VERSION ""

NS_ :

BS_:

BU_: INV BMS VCU BMS Third_Party_Device

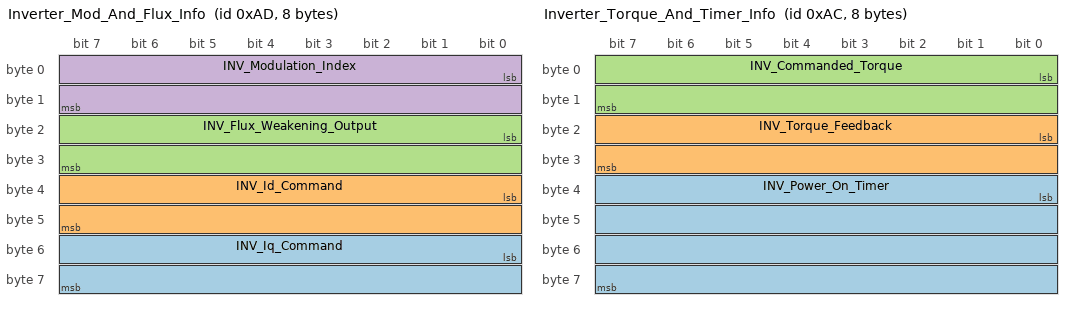
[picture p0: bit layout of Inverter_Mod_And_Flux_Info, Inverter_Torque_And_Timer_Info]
BO_ 173 Inverter_Mod_And_Flux_Info: 8 INV
 SG_ INV_Iq_Command : 48|16@1- (0.1,0) [-3276.8|3276.7] "current:A" Vector__XXX
 SG_ INV_Id_Command : 32|16@1- (0.1,0) [-3276.8|3276.7] "current:A" Vector__XXX
 SG_ INV_Flux_Weakening_Output : 16|16@1- (0.1,0) [-3276.8|3276.7] "current:A" Vector__XXX
 SG_ INV_Modulation_Index : 0|16@1- (0.0001,0) [-3.2768|3.2767] "" Vector__XXX

BO_ 172 Inverter_Torque_And_Timer_Info: 8 INV
 SG_ INV_Power_On_Timer : 32|32@1+ (0.003,0) [0|12884800] "time:second" Vector__XXX
 SG_ INV_Torque_Feedback : 16|16@1- (0.1,0) [-3276.8|3276.7] "torque:N.m" Vector__XXX
 SG_ INV_Commanded_Torque : 0|16@1- (0.1,0) [-3276.8|3276.7] "torque:N.m" Vector__XXX

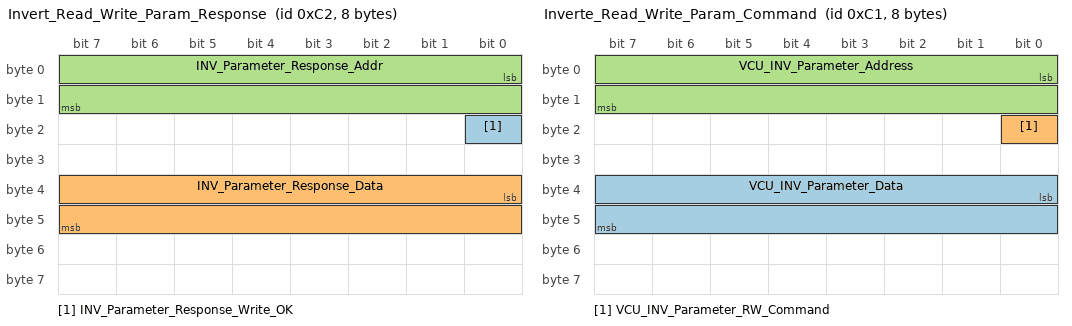
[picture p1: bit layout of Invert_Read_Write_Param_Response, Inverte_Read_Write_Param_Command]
BO_ 194 Invert_Read_Write_Param_Response: 8 INV
 SG_ INV_Parameter_Response_Write_OK : 16|1@1+ (1,0) [0|1] "" Vector__XXX
 SG_ INV_Parameter_Response_Data : 32|16@1- (1,0) [-32768|32767] "" Vector__XXX
 SG_ INV_Parameter_Response_Addr : 0|16@1+ (1,0) [0|65535] "" Vector__XXX

BO_ 193 Inverte_Read_Write_Param_Command: 8 VCU
 SG_ VCU_INV_Parameter_Data : 32|16@1- (1,0) [-32768|32767] "" Vector__XXX
 SG_ VCU_INV_Parameter_RW_Command : 16|1@1+ (1,0) [0|1] "" Vector__XXX
 SG_ VCU_INV_Parameter_Address : 0|16@1+ (1,0) [0|65535] "" Vector__XXX

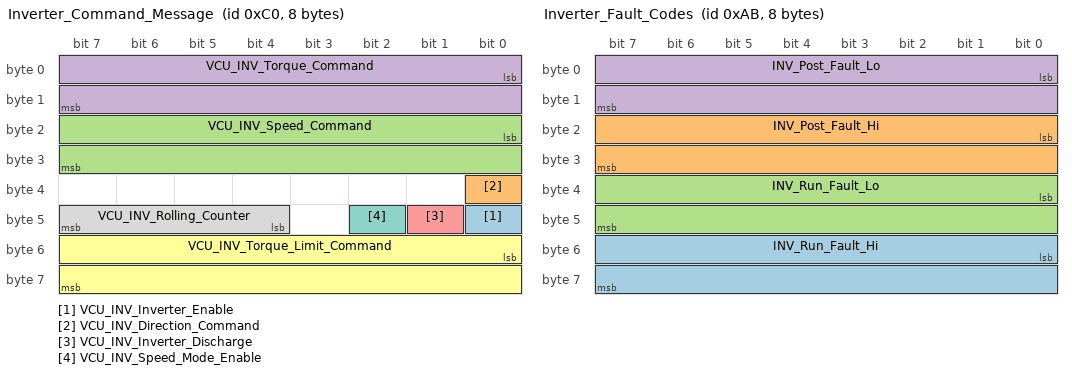
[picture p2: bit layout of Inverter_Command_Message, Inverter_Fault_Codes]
BO_ 192 Inverter_Command_Message: 8 VCU
 SG_ VCU_INV_Inverter_Enable : 40|1@1+ (1,0) [0|1] "" Vector__XXX
 SG_ VCU_INV_Direction_Command : 32|1@1+ (1,0) [0|1] "" Vector__XXX
 SG_ VCU_INV_Speed_Command : 16|16@1- (1,0) [-32768|32767] "angular_speed:rpm" Vector__XXX
 SG_ VCU_INV_Torque_Command : 0|16@1- (0.1,0) [-3276.8|3276.7] "torque:N.m" Vector__XXX
 SG_ VCU_INV_Inverter_Discharge : 41|1@1+ (1,0) [0|1] "" Vector__XXX
 SG_ VCU_INV_Torque_Limit_Command : 48|16@1- (0.1,0) [-3276.8|3276.7] "torque:N.m" Vector__XXX
 SG_ VCU_INV_Speed_Mode_Enable : 42|1@1+ (1,0) [0|1] "" Vector__XXX
 SG_ VCU_INV_Rolling_Counter : 44|4@1+ (1,0) [0|15] "" Vector__XXX

BO_ 171 Inverter_Fault_Codes: 8 INV
 SG_ INV_Run_Fault_Hi : 48|16@1+ (1,0) [0|65535] "" Vector__XXX
 SG_ INV_Post_Fault_Hi : 16|16@1+ (1,0) [0|65535] "" Vector__XXX
 SG_ INV_Run_Fault_Lo : 32|16@1+ (1,0) [0|65535] "" Vector__XXX
 SG_ INV_Post_Fault_Lo : 0|16@1+ (1,0) [0|65535] "" Vector__XXX

BO_ 170 Inverter_Internal_States: 8 INV
 SG_ INV_Direction_Command : 56|1@1+ (1,0) [0|1] "" Vector__XXX
 SG_ INV_Inverter_Enable_State : 48|1@1+ (1,0) [0|1] "" Vector__XXX
 SG_ INV_Relay_3_Status : 26|1@1+ (1,0) [0|1] "" Vector__XXX
 SG_ INV_Relay_4_Status : 27|1@1+ (1,0) [0|1] "" Vector__XXX
 SG_ INV_Relay_2_Status : 25|1@1+ (1,0) [0|1] "" Vector__XXX
 SG_ INV_Inverter_Run_Mode : 32|1@1+ (1,0) [0|1] "" Vector__XXX
 SG_ INV_Inverter_Command_Mode : 40|1@1+ (1,0) [0|1] "" Vector__XXX
 SG_ INV_Relay_1_Status : 24|1@1+ (1,0) [0|1] "" Vector__XXX
 SG_ INV_Inverter_State : 16|8@1+ (1,0) [0|255] "" Vector__XXX
 SG_ INV_VSM_State : 0|8@1+ (1,0) [0|15] "" Vector__XXX
 SG_ INV_Inverter_Enable_Lockout : 55|1@1+ (1,0) [0|1] "" Vector__XXX
 SG_ INV_Inverter_Discharge_State : 37|3@1+ (1,0) [0|7] "" Vector__XXX
 SG_ INV_Relay_5_Status : 28|1@1+ (1,0) [0|1] "" Vector__XXX
 SG_ INV_Relay_6_Status : 29|1@1+ (1,0) [0|1] "" Vector__XXX
 SG_ INV_BMS_Active : 57|1@1+ (1,0) [0|1] "" Vector__XXX
 SG_ INV_BMS_Limiting_Motor_Torque : 58|1@1+ (1,0) [0|1] "" Vector__XXX
 SG_ INV_PWM_Frequency : 8|8@1+ (1,0) [0|255] "" Vector__XXX
 SG_ INV_Limit_Max_Speed : 59|1@1+ (1,0) [0|1] "" Vector__XXX
 SG_ INV_Limit_Hot_Spot : 60|1@1+ (1,0) [0|1] "" Vector__XXX
 SG_ INV_Low_Speed_Limiting : 61|1@1+ (1,0) [0|1] "" Vector__XXX
 SG_ INV_Rolling_Counter : 44|4@1+ (1,0) [0|15] "" Vector__XXX
 SG_ INV_Limit_Coolant_Derating : 62|1@1+ (1,0) [0|1] "" Vector__XXX
 SG_ INV_Self_Sensing_Assist_Enable : 33|1@1+ (1,0) [0|1] "" Vector__XXX
 SG_ INV_Limit_Stall_Burst_Model : 63|1@1+ (1,0) [0|1] "" Vector__XXX
 SG_ INV_Burst_Model_Mode : 49|1@1+ (1,0) [0|1] "" Vector__XXX
 SG_ INV_Key_Switch_Start_Status : 54|1@1+ (1,0) [0|1] "" Vector__XXX
 SG_ INV_BMS_Limiting_Regen_Torque : 50|1@1+ (1,0) [0|0] "" Vector__XXX

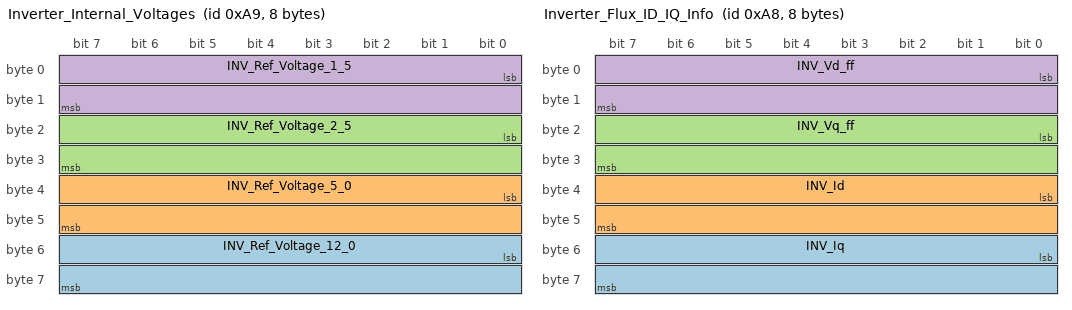
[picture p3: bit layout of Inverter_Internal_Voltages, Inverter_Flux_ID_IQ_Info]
BO_ 169 Inverter_Internal_Voltages: 8 INV
 SG_ INV_Ref_Voltage_12_0 : 48|16@1- (0.01,0) [-327.68|327.67] "voltage:V" Vector__XXX
 SG_ INV_Ref_Voltage_5_0 : 32|16@1- (0.01,0) [-327.68|327.67] "voltage:V" Vector__XXX
 SG_ INV_Ref_Voltage_2_5 : 16|16@1- (0.01,0) [-327.68|327.67] "voltage:V" Vector__XXX
 SG_ INV_Ref_Voltage_1_5 : 0|16@1- (0.01,0) [-327.68|327.67] "voltage:V" Vector__XXX

BO_ 168 Inverter_Flux_ID_IQ_Info: 8 INV
 SG_ INV_Iq : 48|16@1- (0.1,0) [-3276.8|3276.7] "current:A" Vector__XXX
 SG_ INV_Id : 32|16@1- (0.1,0) [-3276.8|3276.7] "current:A" Vector__XXX
 SG_ INV_Vq_ff : 16|16@1- (0.1,0) [-3276.7|3276.7] "voltage:V" Vector__XXX
 SG_ INV_Vd_ff : 0|16@1- (0.1,0) [-3276.7|3276.7] "voltage:V" Vector__XXX

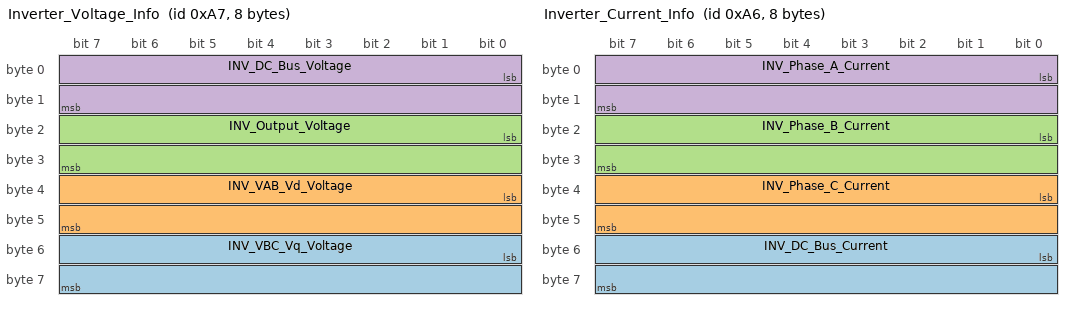
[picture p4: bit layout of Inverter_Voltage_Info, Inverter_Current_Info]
BO_ 167 Inverter_Voltage_Info: 8 INV
 SG_ INV_VBC_Vq_Voltage : 48|16@1- (0.1,0) [-3276.8|3276.7] "voltage:V" Vector__XXX
 SG_ INV_VAB_Vd_Voltage : 32|16@1- (0.1,0) [-3276.8|3276.7] "voltage:V" Vector__XXX
 SG_ INV_Output_Voltage : 16|16@1- (0.1,0) [-3276.8|3276.7] "voltage:V" Vector__XXX
 SG_ INV_DC_Bus_Voltage : 0|16@1- (0.1,0) [-3276.8|3276.7] "voltage:V" Vector__XXX

BO_ 166 Inverter_Current_Info: 8 INV
 SG_ INV_DC_Bus_Current : 48|16@1- (0.1,0) [-3276.8|3276.7] "current:A" Vector__XXX
 SG_ INV_Phase_C_Current : 32|16@1- (0.1,0) [-3276.8|3276.7] "current:A" Vector__XXX
 SG_ INV_Phase_B_Current : 16|16@1- (0.1,0) [-3276.8|3276.7] "current:A" Vector__XXX
 SG_ INV_Phase_A_Current : 0|16@1- (0.1,0) [-3276.8|3276.7] "current:A" Vector__XXX

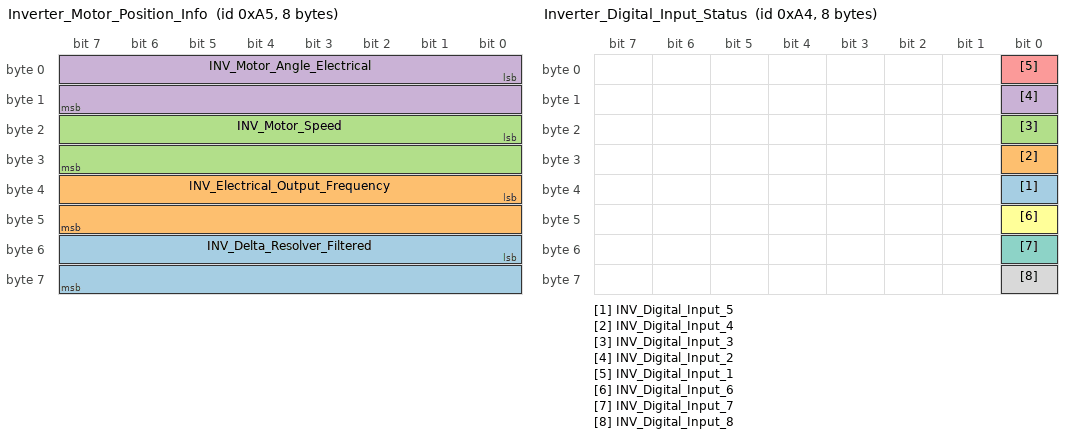
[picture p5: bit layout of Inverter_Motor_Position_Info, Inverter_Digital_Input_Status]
BO_ 165 Inverter_Motor_Position_Info: 8 INV
 SG_ INV_Delta_Resolver_Filtered : 48|16@1- (0.1,0) [-3276.8|3276.7] "angle:deg" Vector__XXX
 SG_ INV_Electrical_Output_Frequency : 32|16@1- (0.1,0) [-3276.8|3276.7] "frequency:Hz" Vector__XXX
 SG_ INV_Motor_Speed : 16|16@1- (1,0) [-32768|32767] "angular_speed:rpm" Vector__XXX
 SG_ INV_Motor_Angle_Electrical : 0|16@1+ (0.1,0) [0|6553.5] "angle:deg" Vector__XXX

BO_ 164 Inverter_Digital_Input_Status: 8 INV
 SG_ INV_Digital_Input_5 : 32|1@1+ (1,0) [0|1] "" Vector__XXX
 SG_ INV_Digital_Input_4 : 24|1@1+ (1,0) [0|1] "" Vector__XXX
 SG_ INV_Digital_Input_3 : 16|1@1+ (1,0) [0|1] "" Vector__XXX
 SG_ INV_Digital_Input_2 : 8|1@1+ (1,0) [0|1] "" Vector__XXX
 SG_ INV_Digital_Input_1 : 0|1@1+ (1,0) [0|1] "" Vector__XXX
 SG_ INV_Digital_Input_6 : 40|1@1+ (1,0) [0|1] "" Vector__XXX
 SG_ INV_Digital_Input_7 : 48|1@1+ (1,0) [0|1] "" Vector__XXX
 SG_ INV_Digital_Input_8 : 56|1@1+ (1,0) [0|1] "" Vector__XXX

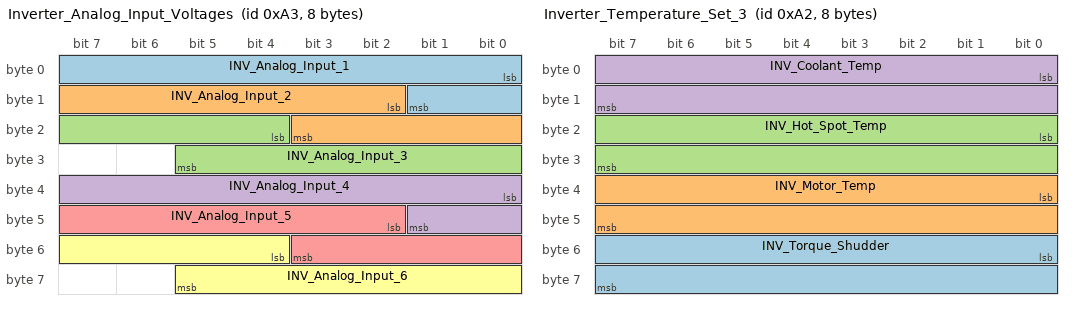
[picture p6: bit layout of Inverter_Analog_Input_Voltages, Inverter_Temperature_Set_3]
BO_ 163 Inverter_Analog_Input_Voltages: 8 INV
 SG_ INV_Analog_Input_1 : 0|10@1+ (0.01,0) [0|10.23] "voltage:V" Vector__XXX
 SG_ INV_Analog_Input_2 : 10|10@1+ (0.01,0) [0|10.23] "voltage:V" Vector__XXX
 SG_ INV_Analog_Input_3 : 20|10@1+ (0.01,0) [0|10.23] "voltage:V" Vector__XXX
 SG_ INV_Analog_Input_4 : 32|10@1+ (0.01,0) [0|10.23] "voltage:V" Vector__XXX
 SG_ INV_Analog_Input_5 : 42|10@1+ (0.01,0) [0|10.23] "voltage:V" Vector__XXX
 SG_ INV_Analog_Input_6 : 52|10@1+ (0.01,0) [0|10.23] "voltage:V" Vector__XXX

BO_ 162 Inverter_Temperature_Set_3: 8 INV
 SG_ INV_Torque_Shudder : 48|16@1- (0.1,0) [-3276.8|3276.7] "torque:N.m" Vector__XXX
 SG_ INV_Motor_Temp : 32|16@1- (0.1,0) [-3276.8|3276.7] "temperature:C" Vector__XXX
 SG_ INV_Hot_Spot_Temp : 16|16@1- (0.1,0) [-3276.8|3276.7] "temperature:C" Vector__XXX
 SG_ INV_Coolant_Temp : 0|16@1- (0.1,0) [-3276.8|3276.7] "temperature:C" Vector__XXX

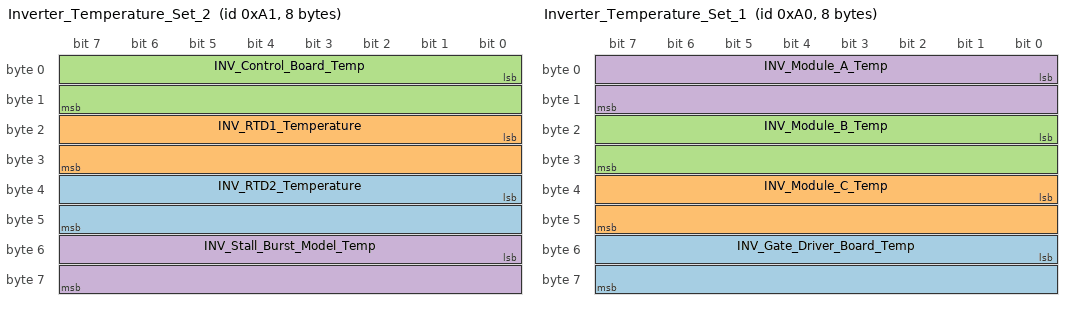
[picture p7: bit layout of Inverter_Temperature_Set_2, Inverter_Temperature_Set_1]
BO_ 161 Inverter_Temperature_Set_2: 8 INV
 SG_ INV_RTD2_Temperature : 32|16@1- (0.1,0) [-3276.8|3276.7] "temperature:C" Vector__XXX
 SG_ INV_RTD1_Temperature : 16|16@1- (0.1,0) [-3276.8|3276.7] "temperature:C" Vector__XXX
 SG_ INV_Control_Board_Temp : 0|16@1- (0.1,0) [-3276.8|3276.7] "temperature:C" Vector__XXX
 SG_ INV_Stall_Burst_Model_Temp : 48|16@1- (0.1,0) [-3276.8|3276.7] "temperature:C" Vector__XXX

BO_ 160 Inverter_Temperature_Set_1: 8 INV
 SG_ INV_Gate_Driver_Board_Temp : 48|16@1- (0.1,0) [-3276.8|3276.7] "temperature:C" Vector__XXX
 SG_ INV_Module_C_Temp : 32|16@1- (0.1,0) [-3276.8|3276.7] "temperature:C" Vector__XXX
 SG_ INV_Module_B_Temp : 16|16@1- (0.1,0) [-3276.8|3276.7] "temperature:C" Vector__XXX
 SG_ INV_Module_A_Temp : 0|16@1- (0.1,0) [-3276.8|3276.7] "temperature:C" Vector__XXX

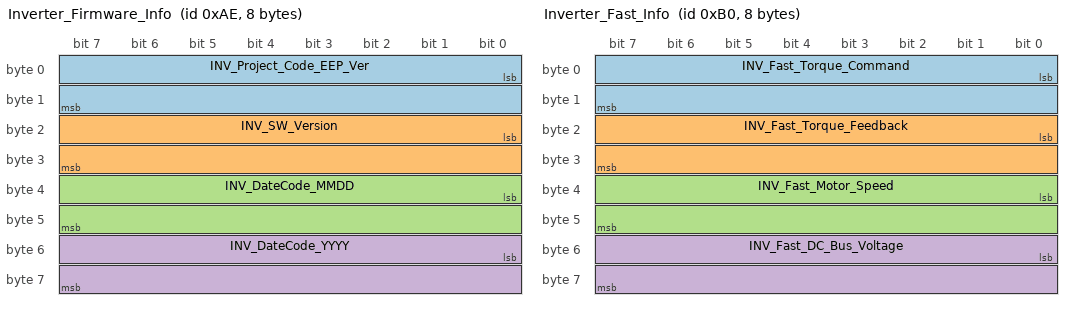
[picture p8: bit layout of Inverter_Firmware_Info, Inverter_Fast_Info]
BO_ 174 Inverter_Firmware_Info: 8 INV
 SG_ INV_Project_Code_EEP_Ver : 0|16@1+ (1,0) [0|65535] "" Vector__XXX
 SG_ INV_SW_Version : 16|16@1+ (1,0) [0|65535] "" Vector__XXX
 SG_ INV_DateCode_MMDD : 32|16@1+ (1,0) [0|65535] "" Vector__XXX
 SG_ INV_DateCode_YYYY : 48|16@1+ (1,0) [0|65535] "" Vector__XXX

BO_ 175 Inverter_Diag_Data_Message: 8 INV
 SG_ INV_Diag_Record : 0|8@1+ (1,0) [0|160] "" Vector__XXX
 SG_ INV_Diag_Segment M : 8|8@1+ (1,0) [0|5] "" Vector__XXX
 SG_ INV_Diag_Gamma_Resolver m0 : 16|16@1- (0.1,0) [0|360] "angle:deg" Vector__XXX
 SG_ INV_Diag_Gamma_Observer m0 : 32|16@1- (0.1,0) [0|360] "angle:deg" Vector__XXX
 SG_ INV_Diag_Sin_Used m0 : 48|16@1- (1,0) [-5|5] "voltage:V" Vector__XXX
 SG_ INV_Diag_Cos_Used m1 : 16|16@1- (1,0) [-5|5] "voltage:V" Vector__XXX
 SG_ INV_Diag_Ia m1 : 32|16@1- (0.1,0) [-2000|2000] "current:A" Vector__XXX
 SG_ INV_Diag_Ib m1 : 48|16@1- (0.1,0) [-2000|2000] "current:A" Vector__XXX
 SG_ INV_Diag_Ic m2 : 16|16@1- (0.1,0) [-2000|2000] "current:A" Vector__XXX
 SG_ INV_Diag_Vdc m2 : 32|16@1- (0.1,0) [0|1000] "voltage:V" Vector__XXX
 SG_ INV_Diag_Iq_cmd m2 : 48|16@1- (0.1,0) [-2000|2000] "current:A" Vector__XXX
 SG_ INV_Diag_Id_cmd m3 : 16|16@1- (0.1,0) [-2000|2000] "current:A" Vector__XXX
 SG_ INV_Diag_Mod_Index m3 : 32|16@1- (0.0001,0) [0|2] "" Vector__XXX
 SG_ INV_Diag_FW_Output m3 : 48|16@1- (0.1,0) [-2000|2000] "current:A" Vector__XXX
 SG_ INV_Diag_Vq_Cmd m4 : 16|16@1- (0.1,0) [-1000|1000] "voltage:V" Vector__XXX
 SG_ INV_Diag_Vd_Cmd m4 : 32|16@1- (0.1,0) [-1000|1000] "voltage:V" Vector__XXX
 SG_ INV_Diag_Vqs_Cmd m4 : 48|16@1- (0.1,0) [-1000|1000] "voltage:V" Vector__XXX
 SG_ INV_Diag_PWM_Freq m5 : 16|16@1+ (1,0) [0|24] "frequency:kHz" Vector__XXX
 SG_ INV_Diag_Run_Faults_Lo m5 : 32|16@1+ (1,0) [0|65535] "" Vector__XXX
 SG_ INV_Diag_Run_Faults_Hi m5 : 48|16@1+ (1,0) [0|65535] "" Vector__XXX

BO_ 514 BMS_Current_Limit: 8 BMS
 SG_ BMS_Max_Discharge_Current : 0|16@1+ (1,0) [0|1000] "current:A" Vector__XXX
 SG_ BMS_Max_Charge_Current : 16|16@1+ (1,0) [0|1000] "current:A" Vector__XXX

BO_ 176 Inverter_Fast_Info: 8 INV
 SG_ INV_Fast_Torque_Command : 0|16@1- (0.1,0) [-3276.8|32767.7] "torque:N.m" Vector__XXX
 SG_ INV_Fast_Torque_Feedback : 16|16@1- (0.1,0) [-3276.8|3276.7] "torque:N.m" Vector__XXX
 SG_ INV_Fast_Motor_Speed : 32|16@1- (1,0) [-32768|32767] "angular_speed:rpm" Vector__XXX
 SG_ INV_Fast_DC_Bus_Voltage : 48|16@1- (0.1,0) [-3276.8|3276.7] "voltage:V" Vector__XXX

BO_ 177 Inverter_Torque_Capability: 8 INV
 SG_ INV_Torque_Capability_Motor : 0|16@1- (0.1,0) [0|3276.7] "torque:N.m" Vector__XXX
 SG_ INV_Torque_Capability_Regen : 16|16@1- (0.1,0) [-3276.8|0] "torque:N.m" Vector__XXX

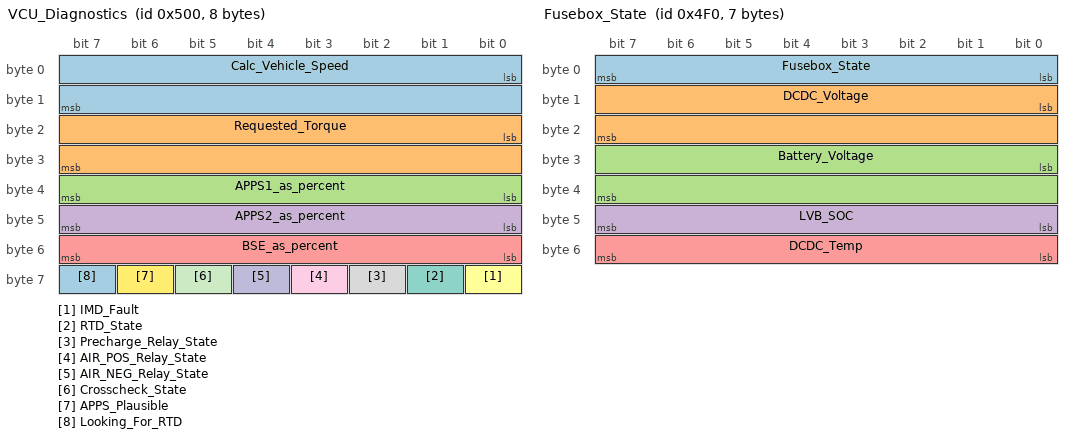
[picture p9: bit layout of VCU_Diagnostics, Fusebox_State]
BO_ 1280 VCU_Diagnostics: 8 Vector__XXX
 SG_ Calc_Vehicle_Speed : 0|16@1- (1,0) [-32767|32768] "mph" Vector__XXX
 SG_ Requested_Torque : 16|16@1- (1,0) [-32767|32768] "Nm" Vector__XXX
 SG_ APPS1_as_percent : 32|8@1- (1,0) [-127|128] "%" Vector__XXX
 SG_ APPS2_as_percent : 40|8@1- (1,0) [-127|128] "%" Vector__XXX
 SG_ BSE_as_percent : 48|8@1- (1,0) [-128|128] "%" Vector__XXX
 SG_ IMD_Fault : 56|1@1+ (1,0) [0|1] "Bool" Vector__XXX
 SG_ RTD_State : 57|1@1+ (1,0) [0|1] "Bool" Vector__XXX
 SG_ Precharge_Relay_State : 58|1@1+ (1,0) [0|1] "Bool" Vector__XXX
 SG_ AIR_POS_Relay_State : 59|1@1+ (1,0) [0|1] "Bool" Vector__XXX
 SG_ AIR_NEG_Relay_State : 60|1@1+ (1,0) [0|1] "Bool" Vector__XXX
 SG_ Crosscheck_State : 61|1@1+ (1,0) [0|1] "Bool" Vector__XXX
 SG_ APPS_Plausible : 62|1@1+ (1,0) [0|1] "Bool" Vector__XXX
 SG_ Looking_For_RTD : 63|1@1+ (1,0) [0|1] "Bool" Vector__XXX

BO_ 1264 Fusebox_State: 7 Vector__XXX
 SG_ Fusebox_State : 0|8@1+ (1,0) [0|5] "State" Vector__XXX
 SG_ DCDC_Voltage : 8|16@1+ (1,0) [0|65535] "mV" Vector__XXX
 SG_ Battery_Voltage : 24|16@1+ (1,0) [0|65535] "mV" Vector__XXX
 SG_ LVB_SOC : 40|8@1+ (1,0) [0|100] "Percent" Vector__XXX
 SG_ DCDC_Temp : 48|8@1+ (10,0) [0|800] "C" Vector__XXX

BO_ 1712 MSGID_0X6B0: 8 BMS
 SG_ Pack_Current : 7|16@0- (0.1,0) [-32769|32767] "Amps"  Third_Party_Device
 SG_ Pack_Summed_Voltage : 23|16@0+ (0.1,0) [0|65535] "Volts"  Third_Party_Device
 SG_ Pack_SOC : 39|8@0+ (0.5,0) [0|255] "Percent"  Third_Party_Device
 SG_ MultiPurpose_Input_2 : 40|1@1+ (1.0,0) [0|1] ""  Third_Party_Device
 SG_ MultiPurpose_Input_3 : 41|1@1+ (1.0,0) [0|1] ""  Third_Party_Device
 SG_ Blank : 42|1@1+ (1.0,0) [0|1] ""  Third_Party_Device
 SG_ MultiPurpose_Output_2 : 43|1@1+ (1.0,0) [0|1] ""  Third_Party_Device
 SG_ MultiPurpose_Output_3 : 44|1@1+ (1.0,0) [0|1] ""  Third_Party_Device
 SG_ MultiPurpose_Output_4 : 45|1@1+ (1.0,0) [0|1] ""  Third_Party_Device
 SG_ MultiPurpose_Enable : 46|1@1+ (1.0,0) [0|1] ""  Third_Party_Device
 SG_ MultiPurpose_Output : 47|1@1+ (1.0,0) [0|1] ""  Third_Party_Device
 SG_ Discharge_Relay : 48|1@1+ (1.0,0) [0|1] ""  Third_Party_Device
 SG_ Charge_Relay : 49|1@1+ (1.0,0) [0|1] ""  Third_Party_Device
 SG_ Charger_Safety : 50|1@1+ (1.0,0) [0|1] ""  Third_Party_Device
 SG_ Error_MIL_Output : 51|1@1+ (1.0,0) [0|1] ""  Third_Party_Device
 SG_ MultiPurpose_Input : 52|1@1+ (1.0,0) [0|1] ""  Third_Party_Device
 SG_ Constant_1 : 53|1@1+ (1.0,0) [0|1] ""  Third_Party_Device
 SG_ Ready_Power_Signal : 54|1@1+ (1.0,0) [0|1] ""  Third_Party_Device
 SG_ Charge_Power_Signal : 55|1@1+ (1.0,0) [0|1] ""  Third_Party_Device
 SG_ CRC_Checksum : 63|8@0+ (1.0,1) [0|0] ""  Third_Party_Device

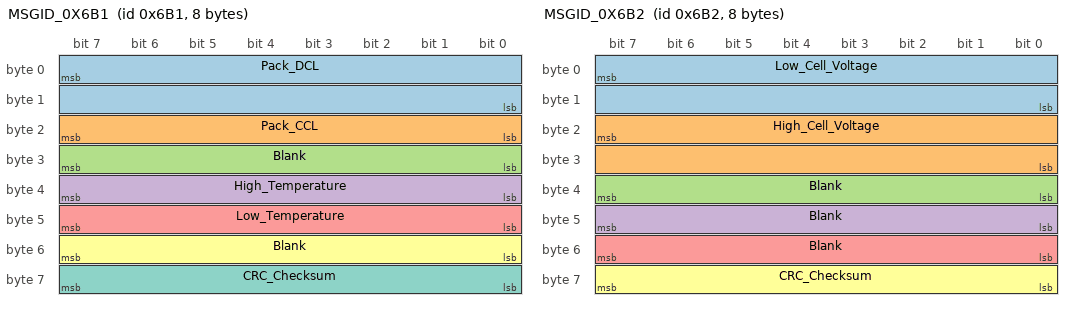
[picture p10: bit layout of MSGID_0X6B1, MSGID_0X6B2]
BO_ 1713 MSGID_0X6B1: 8 BMS
 SG_ Pack_DCL : 7|16@0+ (1.0,0) [0|65535] "Amps"  Third_Party_Device
 SG_ Pack_CCL : 23|8@0+ (1.0,0) [0|255] "Amps"  Third_Party_Device
 SG_ Blank : 31|8@0+ (1.0,0) [0|0] ""  Third_Party_Device
 SG_ High_Temperature : 39|8@0- (1,0) [0|65535] "Celsius"  Third_Party_Device
 SG_ Low_Temperature : 47|8@0- (1,0) [0|65535] "Celsius"  Third_Party_Device
 SG_ Blank : 55|8@0+ (1.0,0) [0|0] ""  Third_Party_Device
 SG_ CRC_Checksum : 63|8@0+ (1.0,1721) [0|0] ""  Third_Party_Device

BO_ 1714 MSGID_0X6B2: 8 BMS
 SG_ Low_Cell_Voltage : 7|16@0+ (1.0E-4,0) [0|65535] "Volts"  Third_Party_Device
 SG_ High_Cell_Voltage : 23|16@0+ (1.0E-4,0) [0|65535] "Volts"  Third_Party_Device
 SG_ Blank : 39|8@0+ (1.0,0) [0|0] ""  Third_Party_Device
 SG_ Blank : 47|8@0+ (1.0,0) [0|0] ""  Third_Party_Device
 SG_ Blank : 55|8@0+ (1.0,0) [0|0] ""  Third_Party_Device
 SG_ CRC_Checksum : 63|8@0+ (1.0,0) [0|0] ""  Third_Party_Device

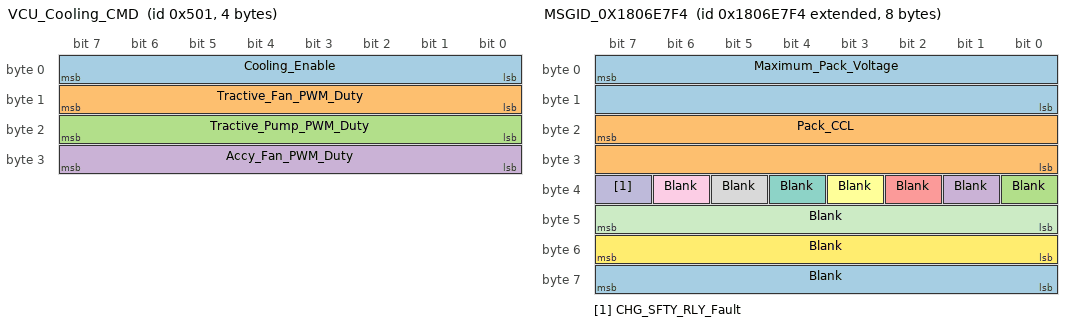
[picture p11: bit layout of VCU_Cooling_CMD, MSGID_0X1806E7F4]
BO_ 1281 VCU_Cooling_CMD: 4 Third_Party_Device
 SG_ Cooling_Enable : 0|8@1+ (1,0) [0|0] "ON/OFF"  BMS
 SG_ Tractive_Fan_PWM_Duty : 8|8@1+ (1,0) [0|100] "Duty Cycle"  BMS
 SG_ Tractive_Pump_PWM_Duty : 16|8@1+ (1,0) [0|100] "Duty Cycle" Vector__XXX
 SG_ Accy_Fan_PWM_Duty : 24|8@1+ (1,0) [0|100] "Duty Cycle" Vector__XXX

BO_ 2550589428 MSGID_0X1806E7F4: 8 BMS
 SG_ Maximum_Pack_Voltage : 7|16@0+ (0.1,0) [0|0] "Volts"  Third_Party_Device
 SG_ Pack_CCL : 23|16@0+ (0.1,0) [0|0] "Amps"  Third_Party_Device
 SG_ Blank : 32|1@1+ (1.0,0) [0|1] ""  Third_Party_Device
 SG_ Blank : 33|1@1+ (1.0,0) [0|1] ""  Third_Party_Device
 SG_ Blank : 34|1@1+ (1.0,0) [0|1] ""  Third_Party_Device
 SG_ Blank : 35|1@1+ (1.0,0) [0|1] ""  Third_Party_Device
 SG_ Blank : 36|1@1+ (1.0,0) [0|1] ""  Third_Party_Device
 SG_ Blank : 37|1@1+ (1.0,0) [0|1] ""  Third_Party_Device
 SG_ Blank : 38|1@1+ (1.0,0) [0|1] ""  Third_Party_Device
 SG_ CHG_SFTY_RLY_Fault : 39|1@1+ (1,0) [0|1] ""  Third_Party_Device
 SG_ Blank : 47|8@0+ (0.1,0) [0|0] ""  Third_Party_Device
 SG_ Blank : 55|8@0+ (1.0,0) [0|0] ""  Third_Party_Device
 SG_ Blank : 63|8@0+ (1.0,0) [0|0] ""  Third_Party_Device

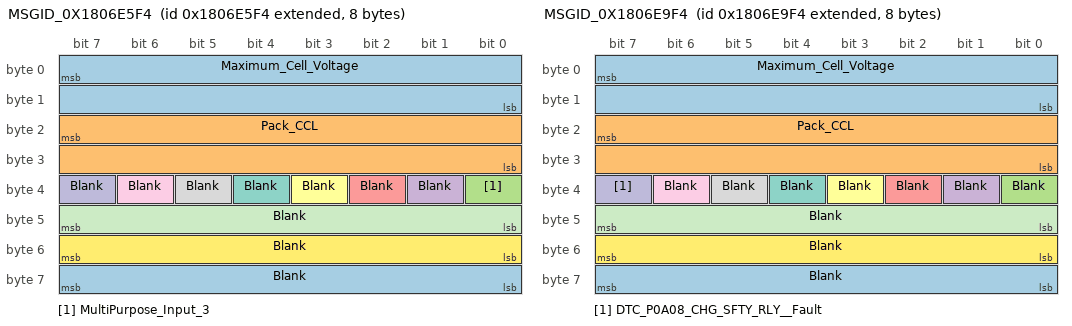
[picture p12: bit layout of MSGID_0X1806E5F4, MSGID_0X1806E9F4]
BO_ 2550588916 MSGID_0X1806E5F4: 8 BMS
 SG_ Maximum_Cell_Voltage : 7|16@0+ (0.001,0) [0|0] "Volts"  Third_Party_Device
 SG_ Pack_CCL : 23|16@0+ (0.1,0) [0|0] "Amps"  Third_Party_Device
 SG_ MultiPurpose_Input_3 : 32|1@1+ (1,0) [0|1] ""  Third_Party_Device
 SG_ Blank : 33|1@1+ (1.0,0) [0|1] ""  Third_Party_Device
 SG_ Blank : 34|1@1+ (1.0,0) [0|1] ""  Third_Party_Device
 SG_ Blank : 35|1@1+ (1.0,0) [0|1] ""  Third_Party_Device
 SG_ Blank : 36|1@1+ (1.0,0) [0|1] ""  Third_Party_Device
 SG_ Blank : 37|1@1+ (1.0,0) [0|1] ""  Third_Party_Device
 SG_ Blank : 38|1@1+ (1.0,0) [0|1] ""  Third_Party_Device
 SG_ Blank : 39|1@1+ (1.0,0) [0|1] ""  Third_Party_Device
 SG_ Blank : 47|8@0+ (1.0,4) [0|0] ""  Third_Party_Device
 SG_ Blank : 55|8@0+ (1.0,0) [0|0] ""  Third_Party_Device
 SG_ Blank : 63|8@0+ (1.0,0) [0|0] ""  Third_Party_Device

BO_ 2550589940 MSGID_0X1806E9F4: 8 BMS
 SG_ Maximum_Cell_Voltage : 7|16@0+ (0.001,0) [0|0] "Volts"  Third_Party_Device
 SG_ Pack_CCL : 23|16@0+ (0.1,0) [0|0] "Amps"  Third_Party_Device
 SG_ Blank : 32|1@1+ (1.0,0) [0|1] ""  Third_Party_Device
 SG_ Blank : 33|1@1+ (1.0,0) [0|1] ""  Third_Party_Device
 SG_ Blank : 34|1@1+ (1.0,0) [0|1] ""  Third_Party_Device
 SG_ Blank : 35|1@1+ (1.0,0) [0|1] ""  Third_Party_Device
 SG_ Blank : 36|1@1+ (1.0,0) [0|1] ""  Third_Party_Device
 SG_ Blank : 37|1@1+ (1.0,0) [0|1] ""  Third_Party_Device
 SG_ Blank : 38|1@1+ (1.0,0) [0|1] ""  Third_Party_Device
 SG_ DTC_P0A08_CHG_SFTY_RLY__Fault : 39|1@1+ (1,0) [0|1] ""  Third_Party_Device
 SG_ Blank : 47|8@0+ (1.0,0) [0|0] ""  Third_Party_Device
 SG_ Blank : 55|8@0+ (1.0,0) [0|0] ""  Third_Party_Device
 SG_ Blank : 63|8@0+ (1.0,0) [0|0] ""  Third_Party_Device

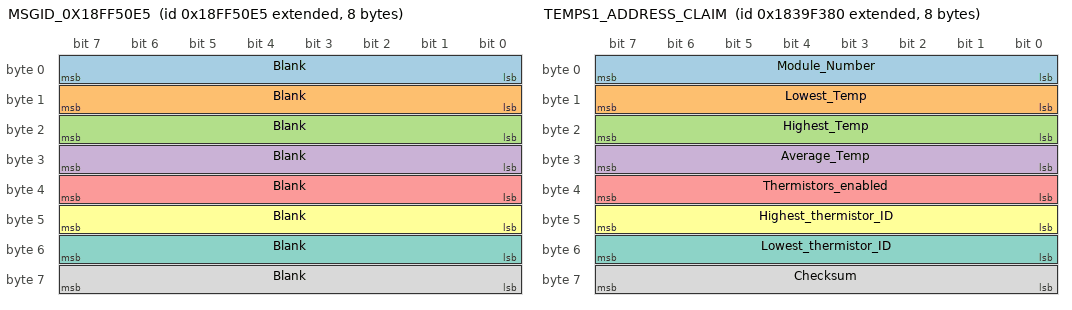
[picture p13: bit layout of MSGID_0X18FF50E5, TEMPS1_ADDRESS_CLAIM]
BO_ 2566869221 MSGID_0X18FF50E5: 8 Third_Party_Device
 SG_ Blank : 7|8@0+ (1.0,0) [0|0] ""  BMS
 SG_ Blank : 15|8@0+ (1.0,0) [0|0] ""  BMS
 SG_ Blank : 23|8@0+ (1.0,0) [0|0] ""  BMS
 SG_ Blank : 31|8@0+ (1.0,0) [0|0] ""  BMS
 SG_ Blank : 39|8@0+ (1.0,0) [0|0] ""  BMS
 SG_ Blank : 47|8@0+ (1.0,0) [0|0] ""  BMS
 SG_ Blank : 55|8@0+ (1.0,0) [0|0] ""  BMS
 SG_ Blank : 63|8@0+ (1.0,0) [0|0] ""  BMS

BO_ 2553934720 TEMPS1_ADDRESS_CLAIM: 8 Vector__XXX
 SG_ Module_Number : 0|8@1+ (1,0) [0|5] "" Vector__XXX
 SG_ Lowest_Temp : 8|8@1+ (1,0) [0|200] "C" Vector__XXX
 SG_ Highest_Temp : 16|8@1+ (1,0) [0|200] "C" Vector__XXX
 SG_ Average_Temp : 24|8@1+ (1,0) [0|200] "C" Vector__XXX
 SG_ Thermistors_enabled : 32|8@1+ (1,0) [0|200] "" Vector__XXX
 SG_ Highest_thermistor_ID : 40|8@1+ (1,0) [0|200] "C" Vector__XXX
 SG_ Lowest_thermistor_ID : 48|8@1+ (1,0) [0|200] "C" Vector__XXX
 SG_ Checksum : 56|8@1+ (1,0) [0|200] "" Vector__XXX

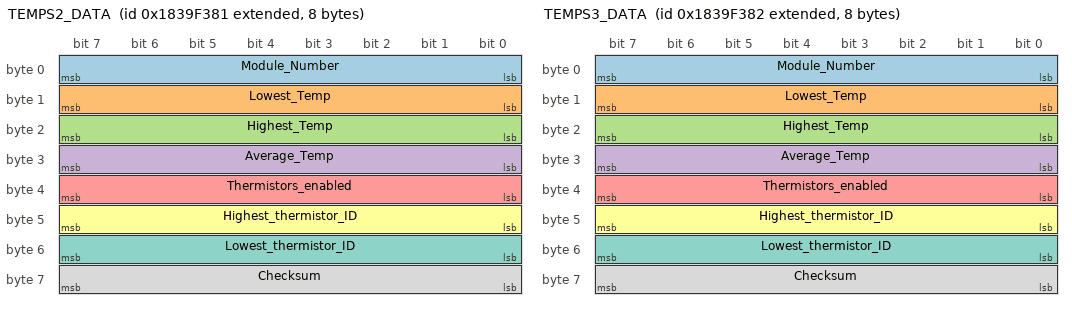
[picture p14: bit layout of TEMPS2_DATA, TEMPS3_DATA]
BO_ 2553934721 TEMPS2_DATA: 8 Vector__XXX
 SG_ Module_Number : 0|8@1+ (1,0) [0|5] "" Vector__XXX
 SG_ Lowest_Temp : 8|8@1+ (1,0) [0|200] "C" Vector__XXX
 SG_ Highest_Temp : 16|8@1+ (1,0) [0|200] "C" Vector__XXX
 SG_ Average_Temp : 24|8@1+ (1,0) [0|200] "C" Vector__XXX
 SG_ Thermistors_enabled : 32|8@1+ (1,0) [0|200] "" Vector__XXX
 SG_ Highest_thermistor_ID : 40|8@1+ (1,0) [0|200] "C" Vector__XXX
 SG_ Lowest_thermistor_ID : 48|8@1+ (1,0) [0|200] "C" Vector__XXX
 SG_ Checksum : 56|8@1+ (1,0) [0|200] "" Vector__XXX

BO_ 2553934722 TEMPS3_DATA: 8 Vector__XXX
 SG_ Module_Number : 0|8@1+ (1,0) [0|5] "" Vector__XXX
 SG_ Lowest_Temp : 8|8@1+ (1,0) [0|200] "C" Vector__XXX
 SG_ Highest_Temp : 16|8@1+ (1,0) [0|200] "C" Vector__XXX
 SG_ Average_Temp : 24|8@1+ (1,0) [0|200] "C" Vector__XXX
 SG_ Thermistors_enabled : 32|8@1+ (1,0) [0|200] "" Vector__XXX
 SG_ Highest_thermistor_ID : 40|8@1+ (1,0) [0|200] "C" Vector__XXX
 SG_ Lowest_thermistor_ID : 48|8@1+ (1,0) [0|200] "C" Vector__XXX
 SG_ Checksum : 56|8@1+ (1,0) [0|200] "" Vector__XXX

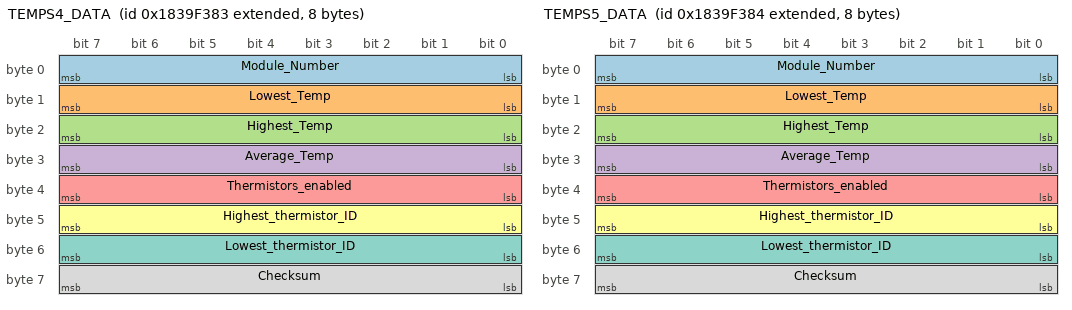
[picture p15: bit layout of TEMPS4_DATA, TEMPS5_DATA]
BO_ 2553934723 TEMPS4_DATA: 8 Vector__XXX
 SG_ Module_Number : 0|8@1+ (1,0) [0|5] "" Vector__XXX
 SG_ Lowest_Temp : 8|8@1+ (1,0) [0|200] "C" Vector__XXX
 SG_ Highest_Temp : 16|8@1+ (1,0) [0|200] "C" Vector__XXX
 SG_ Average_Temp : 24|8@1+ (1,0) [0|200] "C" Vector__XXX
 SG_ Thermistors_enabled : 32|8@1+ (1,0) [0|200] "" Vector__XXX
 SG_ Highest_thermistor_ID : 40|8@1+ (1,0) [0|200] "C" Vector__XXX
 SG_ Lowest_thermistor_ID : 48|8@1+ (1,0) [0|200] "C" Vector__XXX
 SG_ Checksum : 56|8@1+ (1,0) [0|200] "" Vector__XXX

BO_ 2553934724 TEMPS5_DATA: 8 Vector__XXX
 SG_ Module_Number : 0|8@1+ (1,0) [0|5] "" Vector__XXX
 SG_ Lowest_Temp : 8|8@1+ (1,0) [0|200] "C" Vector__XXX
 SG_ Highest_Temp : 16|8@1+ (1,0) [0|200] "C" Vector__XXX
 SG_ Average_Temp : 24|8@1+ (1,0) [0|200] "C" Vector__XXX
 SG_ Thermistors_enabled : 32|8@1+ (1,0) [0|200] "" Vector__XXX
 SG_ Highest_thermistor_ID : 40|8@1+ (1,0) [0|200] "C" Vector__XXX
 SG_ Lowest_thermistor_ID : 48|8@1+ (1,0) [0|200] "C" Vector__XXX
 SG_ Checksum : 56|8@1+ (1,0) [0|200] "" Vector__XXX

BO_ 1715 CustomBMS_DiagInfo: 8 Vector__XXX
 SG_ Precharge_Complete : 0|1@1+ (1,0) [0|1] "" Vector__XXX

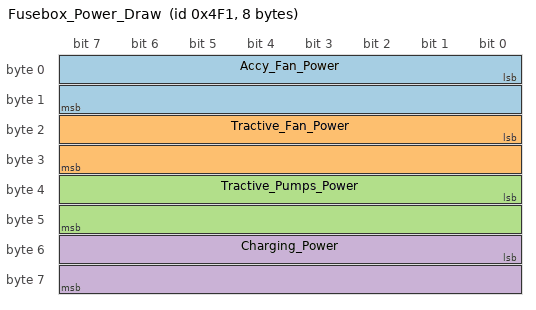
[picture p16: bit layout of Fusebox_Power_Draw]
BO_ 1265 Fusebox_Power_Draw: 8 Vector__XXX
 SG_ Accy_Fan_Power : 0|16@1+ (100,0) [0|65535] "W" Vector__XXX
 SG_ Tractive_Fan_Power : 16|16@1+ (100,0) [0|65535] "W" Vector__XXX
 SG_ Tractive_Pumps_Power : 32|16@1+ (100,0) [0|65535] "W" Vector__XXX
 SG_ Charging_Power : 48|16@1+ (100,0) [0|65535] "W" Vector__XXX

BO_ 1282 VCU_Prechcarge_CMD: 2 Vector__XXX
 SG_ Precharge_CMD : 0|8@1+ (1,0) [0|1] "BOOL" Vector__XXX

BO_ 1266 Fusebox_Secondary_Diag: 8 Vector__XXX
 SG_ Ambient_Temp : 0|8@1+ (1,0) [0|256] "C" Vector__XXX

CM_ SG_ 173 INV_Iq_Command "The commanded Q-axis current";
CM_ SG_ 173 INV_Id_Command "The commanded D-axis current";
CM_ SG_ 173 INV_Flux_Weakening_Output "This is the current output of the flux regulator.";
CM_ SG_ 173 INV_Modulation_Index "This is the modulation index. The scale factor is x100. To get the actual modulation index divide the value by 100.";
CM_ SG_ 172 INV_Power_On_Timer "Updated every 3 msec. This will roll over in approximately 150 days!";
CM_ SG_ 172 INV_Torque_Feedback "Estimated motor torque feedback";
CM_ SG_ 172 INV_Commanded_Torque "The commanded Torque";
CM_ BO_ 194 "To write a parameter use message 0x0C1 with byte #2 set to 1 (write). 
To read a parameter use message 0x0C1 with byte #2 to set 0 (read). ";
CM_ SG_ 194 INV_Parameter_Response_Write_OK "0=Write failure, 1=Success";
CM_ SG_ 194 INV_Parameter_Response_Data "Data from parameter message.  All data is 16 bits and is contained in bytes 4 and 5. Bytes 6 and 7 should be ignored.";
CM_ SG_ 194 INV_Parameter_Response_Addr "Address of parameter response message data.";
CM_ BO_ 193 "To write a parameter use message 0x0C1 with byte #2 set to 1 (write). 
To read a parameter use message 0x0C1 with byte #2 to set 0 (read). ";
CM_ SG_ 193 VCU_INV_Parameter_Data "Data to be written.  All data is 16 bits and is contained in bytes 4 and 5.";
CM_ SG_ 193 VCU_INV_Parameter_RW_Command "0=Read, 1=Write";
CM_ SG_ 193 VCU_INV_Parameter_Address "Address of parameter to be written or read.";
CM_ BO_ 192 "The command message is used to transmit data to the controller. This message is sent from a user supplied external controller to the PMxxx controller.";
CM_ SG_ 192 VCU_INV_Inverter_Enable "0=Inverter OFF, 1 = Inverter ON";
CM_ SG_ 192 VCU_INV_Direction_Command "0=Reverse, 1=Forward.  Forward is positive motor speed.";
CM_ SG_ 192 VCU_INV_Speed_Command "Speed command used when in speed mode";
CM_ SG_ 192 VCU_INV_Torque_Command "Torque command when in torque mode";
CM_ SG_ 192 VCU_INV_Inverter_Discharge "0=Discharge Disable,1=Discharge Enable";
CM_ SG_ 192 VCU_INV_Torque_Limit_Command "Torque Limit, set to 0 to keep default";
CM_ SG_ 192 VCU_INV_Speed_Mode_Enable "0 = No change to mode, 1 = change to speed mode from torque mode";
CM_ SG_ 192 VCU_INV_Rolling_Counter "Rolling Counter sent to inverter.  If used increment count with each message sent.  Otherwise can be set to 0.";
CM_ SG_ 171 INV_Run_Fault_Hi "Each bit represents a fault. Please refer to PM100 Users Manual for details.";
CM_ SG_ 171 INV_Post_Fault_Hi "Each bit represents a fault. Please refer to PM100 Users Manual for details.";
CM_ SG_ 171 INV_Run_Fault_Lo "Each bit represents a fault. Please refer to PM100 Users Manual for details.";
CM_ SG_ 171 INV_Post_Fault_Lo "Each bit represents a fault. Please refer to PM100 Users Manual for details.";
CM_ SG_ 170 INV_Direction_Command "1 = Forward
0 = 'Reverse' if inverter enabled  & 'Stopped' if inverter is disabled";
CM_ SG_ 170 INV_Inverter_Enable_State "0=Inverter Disabled, 
1=Inverter Enabled";
CM_ SG_ 170 INV_Relay_3_Status "0=OFF, 1=ON";
CM_ SG_ 170 INV_Relay_4_Status "0=OFF, 1=ON";
CM_ SG_ 170 INV_Relay_2_Status "0=OFF, 1=ON";
CM_ SG_ 170 INV_Inverter_Run_Mode "0=Torque Mode, 1=Speed Mode";
CM_ SG_ 170 INV_Inverter_Command_Mode "0=CAN mode, 1=VSM mode";
CM_ SG_ 170 INV_Relay_1_Status "0=OFF, 1=ON";
CM_ SG_ 170 INV_Inverter_State "Different states for the inverter state machine";
CM_ SG_ 170 INV_VSM_State "Different states for the vehicle state machine";
CM_ SG_ 170 INV_Inverter_Enable_Lockout "0=Lockout Disabled, 1=Lockout Enabled";
CM_ SG_ 170 INV_Inverter_Discharge_State "0 = Disabled, 1 = Enabled, 2 = Speed Check, 3 = Active, 4 = Complete, 5 = Error, 6 = Override, 7 = Timeout";
CM_ SG_ 170 INV_Relay_5_Status "0=OFF, 1=ON";
CM_ SG_ 170 INV_Relay_6_Status "0=OFF, 1=ON";
CM_ SG_ 170 INV_BMS_Active "0 = BMS Not Active, 1 = BMS Active";
CM_ SG_ 170 INV_BMS_Limiting_Motor_Torque "0 = Not Limiting, 1 = Limiting";
CM_ SG_ 170 INV_PWM_Frequency "The current active PWM frequency";
CM_ SG_ 170 INV_Limit_Max_Speed "Indicates that torque is being modified to limit the speed.";
CM_ SG_ 170 INV_Limit_Hot_Spot "Indicates that torque is being limited to limit the hot spot temp";
CM_ SG_ 170 INV_Low_Speed_Limiting "Indicates that motor current is being limited due to low motor electrical frequency.";
CM_ SG_ 170 INV_Rolling_Counter "Rolling Counter value";
CM_ SG_ 170 INV_Limit_Coolant_Derating "0 = Not limiting, 1 = Limiting";
CM_ SG_ 170 INV_Self_Sensing_Assist_Enable "1 = Self Sensing Assist Enabled, 0 = Self Sensing Assist Disabled";
CM_ SG_ 170 INV_Limit_Stall_Burst_Model "0 = Not limiting, 1 = Limiting";
CM_ SG_ 170 INV_Burst_Model_Mode "0 = Stall, 1 = High Speed";
CM_ SG_ 170 INV_Key_Switch_Start_Status "0 = OFF, 1 = ON";
CM_ SG_ 170 INV_BMS_Limiting_Regen_Torque "0 = Not Limiting, 1 = Limiting";
CM_ SG_ 169 INV_Ref_Voltage_12_0 "12V Input Voltage";
CM_ SG_ 169 INV_Ref_Voltage_5_0 "Transducer voltage";
CM_ SG_ 169 INV_Ref_Voltage_2_5 "Internal reference voltage";
CM_ SG_ 169 INV_Ref_Voltage_1_5 "Internal reference voltage";
CM_ SG_ 168 INV_Iq "The measured Iq current";
CM_ SG_ 168 INV_Id "The measured Id current";
CM_ SG_ 168 INV_Vq_ff "The q-axis voltage feedforward";
CM_ SG_ 168 INV_Vd_ff "The d-axis voltage feedforward";
CM_ SG_ 167 INV_VBC_Vq_Voltage "Measured value of the voltage between Phase B and Phase C";
CM_ SG_ 167 INV_VAB_Vd_Voltage "Measured value of the voltage betwen phase A and Phase B";
CM_ SG_ 167 INV_Output_Voltage "The calculated value of the output voltage, in peak line-neutral volts";
CM_ SG_ 167 INV_DC_Bus_Voltage "The actual measured value of the DC bus voltage";
CM_ SG_ 166 INV_DC_Bus_Current "The Calculated DC Bus Current";
CM_ SG_ 166 INV_Phase_C_Current "The measured value of Phase C current";
CM_ SG_ 166 INV_Phase_B_Current "The measured value of Phase B current";
CM_ SG_ 166 INV_Phase_A_Current "The measured value of Phase A current";
CM_ SG_ 165 INV_Delta_Resolver_Filtered "Used in calibration of resolver angle adjustment.";
CM_ SG_ 165 INV_Electrical_Output_Frequency "The actual electrical frequency of the inverter";
CM_ SG_ 165 INV_Motor_Speed "The measured speed of the motor";
CM_ SG_ 165 INV_Motor_Angle_Electrical "The Electrical Angle of the motor as read by the encoder or resolver";
CM_ SG_ 164 INV_Digital_Input_5 "Status of Digital Input #5";
CM_ SG_ 164 INV_Digital_Input_4 "Status of Digital Input #4";
CM_ SG_ 164 INV_Digital_Input_3 "Status of Digital Input #3";
CM_ SG_ 164 INV_Digital_Input_2 "Status of Digital Input #2";
CM_ SG_ 164 INV_Digital_Input_1 "Status of Digital Input #1";
CM_ SG_ 164 INV_Digital_Input_6 "Status of Digital Input #6";
CM_ SG_ 164 INV_Digital_Input_7 "Status of Digital Input #7";
CM_ SG_ 164 INV_Digital_Input_8 "Status of Digital Input #8";
CM_ SG_ 163 INV_Analog_Input_1 "Voltage on Analog Input #1";
CM_ SG_ 163 INV_Analog_Input_2 "Voltage on Analog Input #2";
CM_ SG_ 163 INV_Analog_Input_3 "Voltage on Analog Input #3";
CM_ SG_ 163 INV_Analog_Input_4 "Voltage on Analog Input #4";
CM_ SG_ 163 INV_Analog_Input_5 "Voltage on Analog Input #5";
CM_ SG_ 163 INV_Analog_Input_6 "Voltage on Analog Input #6";
CM_ SG_ 162 INV_Torque_Shudder "Shudder compensation value of torque";
CM_ SG_ 162 INV_Motor_Temp "Motor Temperature Sensor";
CM_ SG_ 162 INV_Hot_Spot_Temp "Estimated inverter hot spot temperature";
CM_ SG_ 162 INV_Coolant_Temp "Estimated Coolant Temperature";
CM_ SG_ 161 INV_RTD2_Temperature "RTD input 2 (PT1000) Temperature";
CM_ SG_ 161 INV_RTD1_Temperature "RTD input 1 (PT1000) Temperature";
CM_ SG_ 161 INV_Control_Board_Temp "Control Board Temperature";
CM_ SG_ 161 INV_Stall_Burst_Model_Temp "Hottest temperature estimated from the stall burst thermal model feature";
CM_ SG_ 160 INV_Gate_Driver_Board_Temp "Gate Driver Board Temperature";
CM_ SG_ 160 INV_Module_C_Temp "IGBT Module C Temperature";
CM_ SG_ 160 INV_Module_B_Temp "IGBT Module B Temperature";
CM_ SG_ 160 INV_Module_A_Temp "IGBT Module A Temperature";
CM_ BO_ 514 "Sent by BMS";
CM_ SG_ 514 BMS_Max_Discharge_Current "Maximum discharge current from BMS";
CM_ SG_ 514 BMS_Max_Charge_Current "Maximum charge current from BMS";
CM_ BO_ 176 "To enable fast message set CAN ACTIVE MSGS HI WORD to 0xFFFE.  Setting to default value of 0xFFFF will disable the fast message.";
CM_ SG_ 176 INV_Fast_Torque_Command "The commanded torque";
CM_ SG_ 176 INV_Fast_Torque_Feedback "The estimated torque";
CM_ SG_ 176 INV_Fast_Motor_Speed "Motor speed";
CM_ SG_ 176 INV_Fast_DC_Bus_Voltage "DC Bus Voltage";
CM_ SG_ 177 INV_Torque_Capability_Motor "The motoring torque capability of the inverter given the current operating point.";
CM_ SG_ 177 INV_Torque_Capability_Regen "The regen torque capability of the inverter given the current operating point.";
CM_ BO_ 1280 "Diagnostics sent from the VCU. Send every 100ms";
CM_ SG_ 1280 Calc_Vehicle_Speed "Vehicle speed, calculated from motor RPM, in MPH";
CM_ SG_ 1280 Requested_Torque "VCU requested torque in Nm";
CM_ SG_ 1280 APPS1_as_percent "APPS sensor 1, in percent of full travel";
CM_ SG_ 1280 APPS2_as_percent "APPS sensor 2, in percent of full travel";
CM_ SG_ 1280 BSE_as_percent "BSE, in percent of full travel";
CM_ SG_ 1280 IMD_Fault "IMD state: 1 is FAULT, 0 is NO FAULT";
CM_ SG_ 1280 RTD_State "RTD state: 1 is RTD, 0 is NOT RTD";
CM_ SG_ 1280 Precharge_Relay_State "Precharge relay state: 1 is closed, 0 is open";
CM_ SG_ 1280 AIR_POS_Relay_State "Positive AIR relay state: 1 is closed, 0 is open";
CM_ SG_ 1280 AIR_NEG_Relay_State "Negative AIR relay state: 1 is closed, 0 is open";
CM_ SG_ 1280 Crosscheck_State "Crosscheck state: 1 if no problem, 0 if crosscheck fails";
CM_ SG_ 1280 APPS_Plausible "APPS Plausibility state: 1 if no problem, 1 if APPS plausibilty fails";
CM_ SG_ 1280 Looking_For_RTD "Looking for RTD State: 1 if looking, 0 if not";
CM_ BO_ 1264 "Fusebox State. Transmits at 200ms";
CM_ SG_ 1264 Fusebox_State "0 is BATTERY, 1 is DCDCS, 2 is CHARGING BATT";
CM_ SG_ 1264 DCDC_Voltage "DCDC Input Voltage";
CM_ BO_ 1712 "This ID Transmits at 8 ms.";
CM_ BO_ 1713 "This ID Transmits at 104 ms.";
CM_ BO_ 1714 "This ID Transmits at 8 ms.";
CM_ BO_ 2550589428 "This ID Transmits at 808 ms.";
CM_ BO_ 2550588916 "This ID Transmits at 808 ms.";
CM_ BO_ 2550589940 "This ID Transmits at 808 ms.";
CM_ SG_ 1715 Precharge_Complete "1 = Precharge Complete, 0 = Incomplete/Fault";
CM_ BO_ 1281 "VCU Cooling Commands";
CM_ SG_ 1281 Cooling_Enable "1 is enable, 0 is not";
CM_ SG_ 1281 Tractive_Fan_PWM_Duty "Sets Tractive Fan Duty Cycle, out of 255";
CM_ SG_ 1281 Tractive_Pump_PWM_Duty "Sets Tractive Pump Duty Cycle, out of 255";
CM_ SG_ 1281 Accy_Fan_PWM_Duty "Sets Accy Fan Duty Cycle, out of 255";
CM_ BO_ 1265 "Power draws in fusebox. Sends every 50ms";
CM_ SG_ 1265 Accy_Fan_Power "Accy fan power draw, in W";
CM_ SG_ 1265 Tractive_Fan_Power "Tractive fan power draw, in W";
CM_ SG_ 1265 Tractive_Pumps_Power "Tractive Pump power draw, in W";
CM_ SG_ 1265 Charging_Power "Power to charge the battery";
CM_ BO_ 1282 "Command from VCU to BMS to start precharge. sends once and that's it";
CM_ SG_ 1282 Precharge_CMD "sends only when start precharge";
CM_ SG_ 1266 Ambient_Temp "Ambient Temperature; average of all 3 INA238 readings";
BA_DEF_ BO_  "GenMsgCycleTime" INT 0 100000;
BA_DEF_  "BusType" STRING ;
BA_DEF_DEF_  "GenMsgCycleTime" 0;
BA_DEF_DEF_  "BusType" "CAN";
BA_ "GenMsgCycleTime" BO_ 173 10;
BA_ "GenMsgCycleTime" BO_ 172 10;
BA_ "GenMsgCycleTime" BO_ 192 10;
BA_ "GenMsgCycleTime" BO_ 171 10;
BA_ "GenMsgCycleTime" BO_ 170 10;
BA_ "GenMsgCycleTime" BO_ 169 100;
BA_ "GenMsgCycleTime" BO_ 168 10;
BA_ "GenMsgCycleTime" BO_ 167 10;
BA_ "GenMsgCycleTime" BO_ 166 10;
BA_ "GenMsgCycleTime" BO_ 165 10;
BA_ "GenMsgCycleTime" BO_ 164 10;
BA_ "GenMsgCycleTime" BO_ 163 10;
BA_ "GenMsgCycleTime" BO_ 162 100;
BA_ "GenMsgCycleTime" BO_ 161 100;
BA_ "GenMsgCycleTime" BO_ 160 100;
BA_ "GenMsgCycleTime" BO_ 174 100;
BA_ "GenMsgCycleTime" BO_ 175 10;
BA_ "GenMsgCycleTime" BO_ 176 3;
BA_ "GenMsgCycleTime" BO_ 177 10;
VAL_ 192 VCU_INV_Inverter_Enable 0 "Turn the inverter OFF" 1 "Turn the Inverter ON" ;
VAL_ 192 VCU_INV_Direction_Command 0 "CW" 1 "CCW" ;
VAL_ 192 VCU_INV_Inverter_Discharge 0 "Discharge Disable" 1 "Discharge Enable (if EEPROM parameter is set)" ;
VAL_ 170 INV_Inverter_State 0 "Power up" 1 "Stop" 2 "Open Loop" 3 "Closed Loop" 4 "Internal State" 5 "Internal State" 6 "Internal State" 7 "Internal State" 8 "Idle Run" 9 "Idle Stop" 10 "Internal State" 11 "Intern State" 12 "Internal State" ;
VAL_ 170 INV_VSM_State 0 "VSM Start State" 1 "Pre-Charge Init state" 2 "pre-charge active state" 3 "pre-charge complete state" 4 "VSM wait state" 5 "VSM ready state" 6 "Motor Running State" 7 "blink fault code state" 14 "Shutdown state for Key Switch Mode 1" 15 "Reset the inverter" ;
VAL_ 170 INV_Inverter_Discharge_State 0 "Disabled" 1 "Enabled" 2 "Speed Check" 3 "Active" 4 "Complete" 5 "Error" 6 "Override" 7 "Timeout" ;
VAL_ 170 INV_Limit_Stall_Burst_Model 0 "Not Limiting" 1 "Limiting" ;
VAL_ 170 INV_Burst_Model_Mode 0 "Stall" 1 "High Speed" ;
